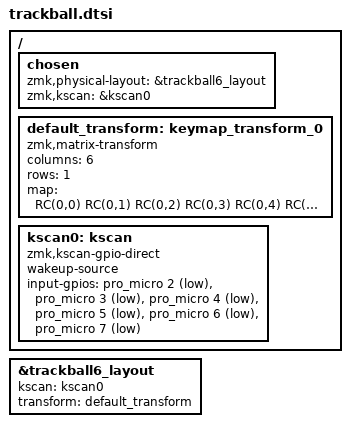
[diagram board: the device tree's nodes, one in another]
/*
 * Copyright (c) 2026
 *
 * SPDX-License-Identifier: MIT
 */

#include <dt-bindings/zmk/matrix_transform.h>
#include "trackball6-layout.dtsi"

&trackball6_layout {
    kscan = <&kscan0>;
    transform = <&default_transform>;
};

/ {
    chosen {
        zmk,physical-layout = &trackball6_layout;
        zmk,kscan = &kscan0;
    };

    default_transform: keymap_transform_0 {
        compatible = "zmk,matrix-transform";
        columns = <6>;
        rows = <1>;
        map = <
            RC(0,0) RC(0,1) RC(0,2) RC(0,3) RC(0,4) RC(0,5)
        >;
    };

    kscan0: kscan {
        compatible = "zmk,kscan-gpio-direct";
        wakeup-source;
        input-gpios
            = <&pro_micro 2 (GPIO_ACTIVE_LOW | GPIO_PULL_UP)>
            , <&pro_micro 3 (GPIO_ACTIVE_LOW | GPIO_PULL_UP)>
            , <&pro_micro 4 (GPIO_ACTIVE_LOW | GPIO_PULL_UP)>
            , <&pro_micro 5 (GPIO_ACTIVE_LOW | GPIO_PULL_UP)>
            , <&pro_micro 6 (GPIO_ACTIVE_LOW | GPIO_PULL_UP)>
            , <&pro_micro 7 (GPIO_ACTIVE_LOW | GPIO_PULL_UP)>
            ;
    };
};
